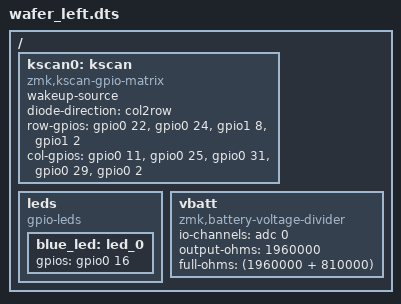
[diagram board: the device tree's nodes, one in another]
/*
 * SPDX-License-Identifier: MIT
 */

#include "wafer.dtsi"

/ {
    kscan0: kscan {
        compatible = "zmk,kscan-gpio-matrix";
        wakeup-source;
        diode-direction = "col2row";
        row-gpios = <&gpio0 22 (GPIO_ACTIVE_HIGH | GPIO_PULL_DOWN)>,
                    <&gpio0 24 (GPIO_ACTIVE_HIGH | GPIO_PULL_DOWN)>,
                    <&gpio1 8 (GPIO_ACTIVE_HIGH | GPIO_PULL_DOWN)>,
                    <&gpio1 2 (GPIO_ACTIVE_HIGH | GPIO_PULL_DOWN)>;
        col-gpios = <&gpio0 11 GPIO_ACTIVE_HIGH>,
                    <&gpio0 25 GPIO_ACTIVE_HIGH>,
                    <&gpio0 31 GPIO_ACTIVE_HIGH>,
                    <&gpio0 29 GPIO_ACTIVE_HIGH>,
                    <&gpio0 2 GPIO_ACTIVE_HIGH>;
    };

    leds {
        compatible = "gpio-leds";
        blue_led: led_0 {
            gpios = <&gpio0 16 GPIO_ACTIVE_HIGH>;
        };
    };

    vbatt: vbatt {
        compatible = "zmk,battery-voltage-divider";
        io-channels = <&adc 0>;
        output-ohms = <1960000>;
        full-ohms = <(1960000 + 810000)>;
    };
};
